AUTOSAR XML (schema 4-2-2)
package /STELLANTIS/EPT/ASWCs
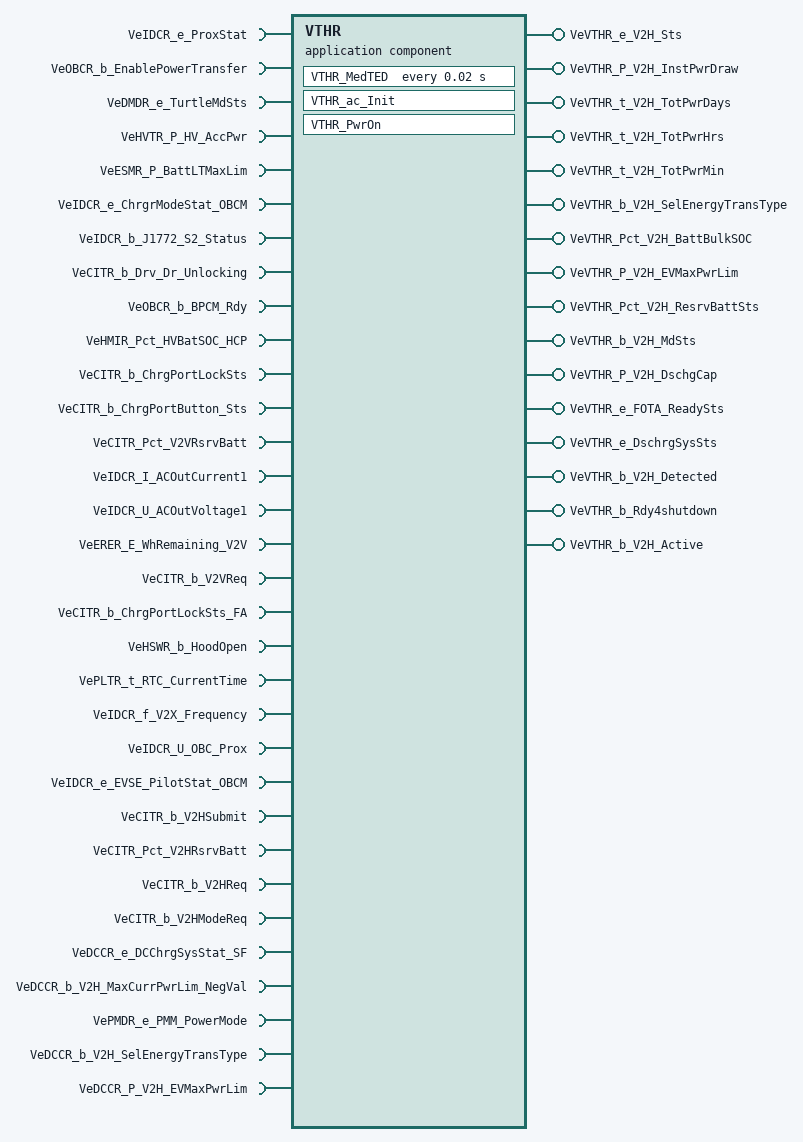
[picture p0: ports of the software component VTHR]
  application sw component type VTHR
    32 x require port:
      VeIDCR_e_ProxStat: variation-point={short-label=vpVeIDCR_e_ProxStat, sw-syscond=1}, nonqueued-receiver-com-spec{data-element=Value, init-value=CeOBCR_e_ProxLo_OBCM}, required-interface=VeIDCR_e_ProxStat
      VeOBCR_b_EnablePowerTransfer: variation-point={short-label=vpVeOBCR_b_EnablePowerTransfer, sw-syscond=1}, nonqueued-receiver-com-spec{data-element=Value, init-value=0}, required-interface=VeOBCR_b_EnablePowerTransfer
      VeDMDR_e_TurtleMdSts: variation-point={short-label=vpVeDMDR_e_TurtleMdSts, sw-syscond=1}, nonqueued-receiver-com-spec{data-element=Value, init-value=CeDMDR_e_No_Turtle_Mode}, required-interface=VeDMDR_e_TurtleMdSts
      VeHVTR_P_HV_AccPwr: variation-point={short-label=vpVeHVTR_P_HV_AccPwr, sw-syscond=1}, nonqueued-receiver-com-spec{data-element=Value, init-value=0}, required-interface=VeHVTR_P_HV_AccPwr
      VeESMR_P_BattLTMaxLim: variation-point={short-label=vpVeESMR_P_BattLTMaxLim, sw-syscond=1}, nonqueued-receiver-com-spec{data-element=Value, init-value=0}, required-interface=VeESMR_P_BattLTMaxLim
      VeIDCR_e_ChrgrModeStat_OBCM: variation-point={short-label=vpVeIDCR_e_ChrgrModeStat_OBCM, sw-syscond=1}, nonqueued-receiver-com-spec{data-element=Value, init-value=CeOBCR_e_Idle_OBCM}, required-interface=VeIDCR_e_ChrgrModeStat_OBCM
      VeIDCR_b_J1772_S2_Status: variation-point={short-label=vpVeIDCR_b_J1772_S2_Status, sw-syscond=1}, nonqueued-receiver-com-spec{data-element=Value, init-value=0}, required-interface=VeIDCR_b_J1772_S2_Status
      VeCITR_b_Drv_Dr_Unlocking: variation-point={short-label=vpVeCITR_b_Drv_Dr_Unlocking, sw-syscond=1}, nonqueued-receiver-com-spec{data-element=Value, init-value=0}, required-interface=VeCITR_b_Drv_Dr_Unlocking
      VeOBCR_b_BPCM_Rdy: variation-point={short-label=vpVeOBCR_b_BPCM_Rdy, sw-syscond=1}, nonqueued-receiver-com-spec{data-element=Value, init-value=0}, required-interface=VeOBCR_b_BPCM_Rdy
      VeHMIR_Pct_HVBatSOC_HCP: variation-point={short-label=vpVeHMIR_Pct_HVBatSOC_HCP, sw-syscond=1}, nonqueued-receiver-com-spec{data-element=Value, init-value=0}, required-interface=VeHMIR_Pct_HVBatSOC_HCP
      VeCITR_b_ChrgPortLockSts: variation-point={short-label=vpVeCITR_b_ChrgPortLockSts, sw-syscond=1}, nonqueued-receiver-com-spec{data-element=Value, init-value=0}, required-interface=VeCITR_b_ChrgPortLockSts
      VeCITR_b_ChrgPortButton_Sts: variation-point={short-label=vpVeCITR_b_ChrgPortButton_Sts, sw-syscond=1}, nonqueued-receiver-com-spec{data-element=Value, init-value=0}, required-interface=VeCITR_b_ChrgPortButton_Sts
      VeCITR_Pct_V2VRsrvBatt: variation-point={short-label=vpVeCITR_Pct_V2VRsrvBatt, sw-syscond=1}, nonqueued-receiver-com-spec{data-element=Value, init-value=0}, required-interface=VeCITR_Pct_V2VRsrvBatt
      VeIDCR_I_ACOutCurrent1: variation-point={short-label=vpVeIDCR_I_ACOutCurrent1, sw-syscond=1}, nonqueued-receiver-com-spec{data-element=Value, init-value=0}, required-interface=VeIDCR_I_ACOutCurrent1
      VeIDCR_U_ACOutVoltage1: variation-point={short-label=vpVeIDCR_U_ACOutVoltage1, sw-syscond=1}, nonqueued-receiver-com-spec{data-element=Value, init-value=0}, required-interface=VeIDCR_U_ACOutVoltage1
      VeERER_E_WhRemaining_V2V: variation-point={short-label=vpVeERER_E_WhRemaining_V2V, sw-syscond=1}, nonqueued-receiver-com-spec{data-element=Value, init-value=0}, required-interface=VeERER_E_WhRemaining_V2V
      VeCITR_b_V2VReq: variation-point={short-label=vpVeCITR_b_V2VReq, sw-syscond=1}, nonqueued-receiver-com-spec{data-element=Value, init-value=0}, required-interface=VeCITR_b_V2VReq
      VeCITR_b_ChrgPortLockSts_FA: variation-point={short-label=vpVeCITR_b_ChrgPortLockSts_FA, sw-syscond=1}, nonqueued-receiver-com-spec{data-element=Value, init-value=0}, required-interface=VeCITR_b_ChrgPortLockSts_FA
      VeHSWR_b_HoodOpen: variation-point={short-label=vpVeHSWR_b_HoodOpen, sw-syscond=1}, nonqueued-receiver-com-spec{data-element=Value, init-value=0}, required-interface=VeHSWR_b_HoodOpen
      VePLTR_t_RTC_CurrentTime: variation-point={short-label=vpVePLTR_t_RTC_CurrentTime, sw-syscond=1}, nonqueued-receiver-com-spec{data-element=Value, init-value=0}, required-interface=VePLTR_t_RTC_CurrentTime
      VeIDCR_f_V2X_Frequency: variation-point={short-label=vpVeIDCR_f_V2X_Frequency, sw-syscond=1}, nonqueued-receiver-com-spec{data-element=Value, init-value=0}, required-interface=VeIDCR_f_V2X_Frequency
      VeIDCR_U_OBC_Prox: variation-point={short-label=vpVeIDCR_U_OBC_Prox, sw-syscond=1}, nonqueued-receiver-com-spec{data-element=Value, init-value=0}, required-interface=VeIDCR_U_OBC_Prox
      VeIDCR_e_EVSE_PilotStat_OBCM: variation-point={short-label=vpVeIDCR_e_EVSE_PilotStat_OBCM, sw-syscond=1}, nonqueued-receiver-com-spec{data-element=Value, init-value=CeOBCR_e_NO_EVSE_OBCM}, required-interface=VeIDCR_e_EVSE_PilotStat_OBCM
      VeCITR_b_V2HSubmit: variation-point={short-label=vpVeCITR_b_V2HSubmit, sw-syscond=1}, nonqueued-receiver-com-spec{data-element=Value, init-value=0}, required-interface=VeCITR_b_V2HSubmit
      VeCITR_Pct_V2HRsrvBatt: variation-point={short-label=vpVeCITR_Pct_V2HRsrvBatt, sw-syscond=1}, nonqueued-receiver-com-spec{data-element=Value, init-value=0}, required-interface=VeCITR_Pct_V2HRsrvBatt
      VeCITR_b_V2HReq: variation-point={short-label=vpVeCITR_b_V2HReq, sw-syscond=1}, nonqueued-receiver-com-spec{data-element=Value, init-value=0}, required-interface=VeCITR_b_V2HReq
      VeCITR_b_V2HModeReq: variation-point={short-label=vpVeCITR_b_V2HModeReq, sw-syscond=1}, nonqueued-receiver-com-spec{data-element=Value, init-value=0}, required-interface=VeCITR_b_V2HModeReq
      VeDCCR_e_DCChrgSysStat_SF: variation-point={short-label=vpVeDCCR_e_DCChrgSysStat_SF, sw-syscond=1}, nonqueued-receiver-com-spec{data-element=Value, init-value=CeOBCR_e_DCinit}, required-interface=VeDCCR_e_DCChrgSysStat_SF
      VeDCCR_b_V2H_MaxCurrPwrLim_NegVal: variation-point={short-label=vpVeDCCR_b_V2H_MaxCurrPwrLim_NegVal, sw-syscond=1}, nonqueued-receiver-com-spec{data-element=Value, init-value=0}, required-interface=VeDCCR_b_V2H_MaxCurrPwrLim_NegVal
      VePMDR_e_PMM_PowerMode: variation-point={short-label=vpVePMDR_e_PMM_PowerMode, sw-syscond=1}, nonqueued-receiver-com-spec{data-element=Value, init-value=CePMDR_e_PowerMode_Off}, required-interface=VePMDR_e_PMM_PowerMode
      VeDCCR_b_V2H_SelEnergyTransType: variation-point={short-label=vpVeDCCR_b_V2H_SelEnergyTransType, sw-syscond=1}, nonqueued-receiver-com-spec{data-element=Value, init-value=0}, required-interface=VeDCCR_b_V2H_SelEnergyTransType
      VeDCCR_P_V2H_EVMaxPwrLim: variation-point={short-label=vpVeDCCR_P_V2H_EVMaxPwrLim, sw-syscond=1}, nonqueued-receiver-com-spec{data-element=Value, init-value=0}, required-interface=VeDCCR_P_V2H_EVMaxPwrLim
    16 x provide port:
      VeVTHR_e_V2H_Sts: nonqueued-sender-com-spec{data-element=Value, init-value=CeVTHR_e_V2H_Inactive}, provided-interface=VeVTHR_e_V2H_Sts
      VeVTHR_P_V2H_InstPwrDraw: nonqueued-sender-com-spec{data-element=Value, init-value=0}, provided-interface=VeVTHR_P_V2H_InstPwrDraw
      VeVTHR_t_V2H_TotPwrDays: nonqueued-sender-com-spec{data-element=Value, init-value=0}, provided-interface=VeVTHR_t_V2H_TotPwrDays
      VeVTHR_t_V2H_TotPwrHrs: nonqueued-sender-com-spec{data-element=Value, init-value=0}, provided-interface=VeVTHR_t_V2H_TotPwrHrs
      VeVTHR_t_V2H_TotPwrMin: nonqueued-sender-com-spec{data-element=Value, init-value=0}, provided-interface=VeVTHR_t_V2H_TotPwrMin
      VeVTHR_b_V2H_SelEnergyTransType: nonqueued-sender-com-spec{data-element=Value, init-value=0}, provided-interface=VeVTHR_b_V2H_SelEnergyTransType
      VeVTHR_Pct_V2H_BattBulkSOC: nonqueued-sender-com-spec{data-element=Value, init-value=0}, provided-interface=VeVTHR_Pct_V2H_BattBulkSOC
      VeVTHR_P_V2H_EVMaxPwrLim: nonqueued-sender-com-spec{data-element=Value, init-value=0}, provided-interface=VeVTHR_P_V2H_EVMaxPwrLim
      VeVTHR_Pct_V2H_ResrvBattSts: nonqueued-sender-com-spec{data-element=Value, init-value=0}, provided-interface=VeVTHR_Pct_V2H_ResrvBattSts
      VeVTHR_b_V2H_MdSts: nonqueued-sender-com-spec{data-element=Value, init-value=0}, provided-interface=VeVTHR_b_V2H_MdSts
      VeVTHR_P_V2H_DschgCap: nonqueued-sender-com-spec{data-element=Value, init-value=0}, provided-interface=VeVTHR_P_V2H_DschgCap
      VeVTHR_e_FOTA_ReadySts: nonqueued-sender-com-spec{data-element=Value, init-value=CeVTHR_e_Eval_in_Progress}, provided-interface=VeVTHR_e_FOTA_ReadySts
      VeVTHR_e_DschrgSysSts: nonqueued-sender-com-spec{data-element=Value, init-value=CeVTHR_e_Inactive}, provided-interface=VeVTHR_e_DschrgSysSts
      VeVTHR_b_V2H_Detected: nonqueued-sender-com-spec{data-element=Value, init-value=0}, provided-interface=VeVTHR_b_V2H_Detected
      VeVTHR_b_Rdy4shutdown: nonqueued-sender-com-spec{data-element=Value, init-value=0}, provided-interface=VeVTHR_b_Rdy4shutdown
      VeVTHR_b_V2H_Active: nonqueued-sender-com-spec{data-element=Value, init-value=0}, provided-interface=VeVTHR_b_V2H_Active
    behavior IB_VTHR: data-type-mapping=msADTtoIDTMapping, handle-termination-and-restart=NO-SUPPORT
      timing event Event_MedTED: start-on-event=VTHR_MedTED, period=0.02
      init event Event_VTHR_ac_Init: start-on-event=VTHR_ac_Init
      init event Event_PwrOn: start-on-event=VTHR_PwrOn
      runnable VTHR_ac_Init
        data-send-points:
          access OUT_VeVTHR_e_V2H_Sts_Value: accessed-variable=VeVTHR_e_V2H_Sts.Value
          access OUT_VeVTHR_e_FOTA_ReadySts_Value: accessed-variable=VeVTHR_e_FOTA_ReadySts.Value
          access OUT_VeVTHR_e_DschrgSysSts_Value: accessed-variable=VeVTHR_e_DschrgSysSts.Value
      runnable VTHR_PwrOn
        data-send-points:
          16 x access:
            OUT_VeVTHR_b_V2H_SelEnergyTransType_Value: accessed-variable=VeVTHR_b_V2H_SelEnergyTransType.Value
            OUT_VeVTHR_Pct_V2H_BattBulkSOC_Value: accessed-variable=VeVTHR_Pct_V2H_BattBulkSOC.Value
            OUT_VeVTHR_P_V2H_EVMaxPwrLim_Value: accessed-variable=VeVTHR_P_V2H_EVMaxPwrLim.Value
            OUT_VeVTHR_Pct_V2H_ResrvBattSts_Value: accessed-variable=VeVTHR_Pct_V2H_ResrvBattSts.Value
            OUT_VeVTHR_b_V2H_MdSts_Value: accessed-variable=VeVTHR_b_V2H_MdSts.Value
            OUT_VeVTHR_P_V2H_DschgCap_Value: accessed-variable=VeVTHR_P_V2H_DschgCap.Value
            OUT_VeVTHR_e_FOTA_ReadySts_Value: accessed-variable=VeVTHR_e_FOTA_ReadySts.Value
            OUT_VeVTHR_e_V2H_Sts_Value: accessed-variable=VeVTHR_e_V2H_Sts.Value
            OUT_VeVTHR_t_V2H_TotPwrHrs_Value: accessed-variable=VeVTHR_t_V2H_TotPwrHrs.Value
            OUT_VeVTHR_t_V2H_TotPwrDays_Value: accessed-variable=VeVTHR_t_V2H_TotPwrDays.Value
            OUT_VeVTHR_t_V2H_TotPwrMin_Value: accessed-variable=VeVTHR_t_V2H_TotPwrMin.Value
            OUT_VeVTHR_P_V2H_InstPwrDraw_Value: accessed-variable=VeVTHR_P_V2H_InstPwrDraw.Value
            OUT_VeVTHR_e_DschrgSysSts_Value: accessed-variable=VeVTHR_e_DschrgSysSts.Value
            OUT_VeVTHR_b_V2H_Detected_Value: accessed-variable=VeVTHR_b_V2H_Detected.Value
            OUT_VeVTHR_b_Rdy4shutdown_Value: accessed-variable=VeVTHR_b_Rdy4shutdown.Value
            OUT_VeVTHR_b_V2H_Active_Value: accessed-variable=VeVTHR_b_V2H_Active.Value
      runnable VTHR_MedTED: variation-point={short-label=vpVTHR_MedTED, sw-syscond=1}
        data-receive-point-by-arguments:
          13 x access:
            IN_VeCITR_b_Drv_Dr_Unlocking_Value: accessed-variable=VeCITR_b_Drv_Dr_Unlocking.Value, variation-point={short-label=vpIN_VeCITR_b_Drv_Dr_Unlocking_Value, sw-syscond=1}
            IN_VeDCCR_b_V2H_MaxCurrPwrLim_NegVal_Value: accessed-variable=VeDCCR_b_V2H_MaxCurrPwrLim_NegVal.Value, variation-point={short-label=vpIN_VeDCCR_b_V2H_MaxCurrPwrLim_NegVal_Value, sw-syscond=1}
            IN_VeDMDR_e_TurtleMdSts_Value: accessed-variable=VeDMDR_e_TurtleMdSts.Value, variation-point={short-label=vpIN_VeDMDR_e_TurtleMdSts_Value, sw-syscond=1}
            IN_VeESMR_P_BattLTMaxLim_Value: accessed-variable=VeESMR_P_BattLTMaxLim.Value, variation-point={short-label=vpIN_VeESMR_P_BattLTMaxLim_Value, sw-syscond=1}
            IN_VeHSWR_b_HoodOpen_Value: accessed-variable=VeHSWR_b_HoodOpen.Value, variation-point={short-label=vpIN_VeHSWR_b_HoodOpen_Value, sw-syscond=1}
            IN_VeHVTR_P_HV_AccPwr_Value: accessed-variable=VeHVTR_P_HV_AccPwr.Value, variation-point={short-label=vpIN_VeHVTR_P_HV_AccPwr_Value, sw-syscond=1}
            IN_VeIDCR_b_J1772_S2_Status_Value: accessed-variable=VeIDCR_b_J1772_S2_Status.Value, variation-point={short-label=vpIN_VeIDCR_b_J1772_S2_Status_Value, sw-syscond=1}
            IN_VeIDCR_e_ChrgrModeStat_OBCM_Value: accessed-variable=VeIDCR_e_ChrgrModeStat_OBCM.Value, variation-point={short-label=vpIN_VeIDCR_e_ChrgrModeStat_OBCM_Value, sw-syscond=1}
            IN_VeIDCR_e_EVSE_PilotStat_OBCM_Value: accessed-variable=VeIDCR_e_EVSE_PilotStat_OBCM.Value, variation-point={short-label=vpIN_VeIDCR_e_EVSE_PilotStat_OBCM_Value, sw-syscond=1}
            IN_VeIDCR_e_ProxStat_Value: accessed-variable=VeIDCR_e_ProxStat.Value, variation-point={short-label=vpIN_VeIDCR_e_ProxStat_Value, sw-syscond=1}
            IN_VeOBCR_b_BPCM_Rdy_Value: accessed-variable=VeOBCR_b_BPCM_Rdy.Value, variation-point={short-label=vpIN_VeOBCR_b_BPCM_Rdy_Value, sw-syscond=1}
            IN_VeOBCR_b_EnablePowerTransfer_Value: accessed-variable=VeOBCR_b_EnablePowerTransfer.Value, variation-point={short-label=vpIN_VeOBCR_b_EnablePowerTransfer_Value, sw-syscond=1}
            IN_VePMDR_e_PMM_PowerMode_Value: accessed-variable=VePMDR_e_PMM_PowerMode.Value, variation-point={short-label=vpIN_VePMDR_e_PMM_PowerMode_Value, sw-syscond=1}
        data-send-points:
          16 x access:
            OUT_VeVTHR_e_V2H_Sts_Value: accessed-variable=VeVTHR_e_V2H_Sts.Value
            OUT_VeVTHR_P_V2H_InstPwrDraw_Value: accessed-variable=VeVTHR_P_V2H_InstPwrDraw.Value
            OUT_VeVTHR_t_V2H_TotPwrDays_Value: accessed-variable=VeVTHR_t_V2H_TotPwrDays.Value
            OUT_VeVTHR_t_V2H_TotPwrHrs_Value: accessed-variable=VeVTHR_t_V2H_TotPwrHrs.Value
            OUT_VeVTHR_t_V2H_TotPwrMin_Value: accessed-variable=VeVTHR_t_V2H_TotPwrMin.Value
            OUT_VeVTHR_b_V2H_SelEnergyTransType_Value: accessed-variable=VeVTHR_b_V2H_SelEnergyTransType.Value
            OUT_VeVTHR_Pct_V2H_BattBulkSOC_Value: accessed-variable=VeVTHR_Pct_V2H_BattBulkSOC.Value
            OUT_VeVTHR_P_V2H_EVMaxPwrLim_Value: accessed-variable=VeVTHR_P_V2H_EVMaxPwrLim.Value
            OUT_VeVTHR_Pct_V2H_ResrvBattSts_Value: accessed-variable=VeVTHR_Pct_V2H_ResrvBattSts.Value
            OUT_VeVTHR_b_V2H_MdSts_Value: accessed-variable=VeVTHR_b_V2H_MdSts.Value
            OUT_VeVTHR_P_V2H_DschgCap_Value: accessed-variable=VeVTHR_P_V2H_DschgCap.Value
            OUT_VeVTHR_e_FOTA_ReadySts_Value: accessed-variable=VeVTHR_e_FOTA_ReadySts.Value
            OUT_VeVTHR_e_DschrgSysSts_Value: accessed-variable=VeVTHR_e_DschrgSysSts.Value
            OUT_VeVTHR_b_V2H_Detected_Value: accessed-variable=VeVTHR_b_V2H_Detected.Value
            OUT_VeVTHR_b_Rdy4shutdown_Value: accessed-variable=VeVTHR_b_Rdy4shutdown.Value
            OUT_VeVTHR_b_V2H_Active_Value: accessed-variable=VeVTHR_b_V2H_Active.Value
      variation point proxy Variant_VTHR_3: category=CONDITION, condition-access=1
